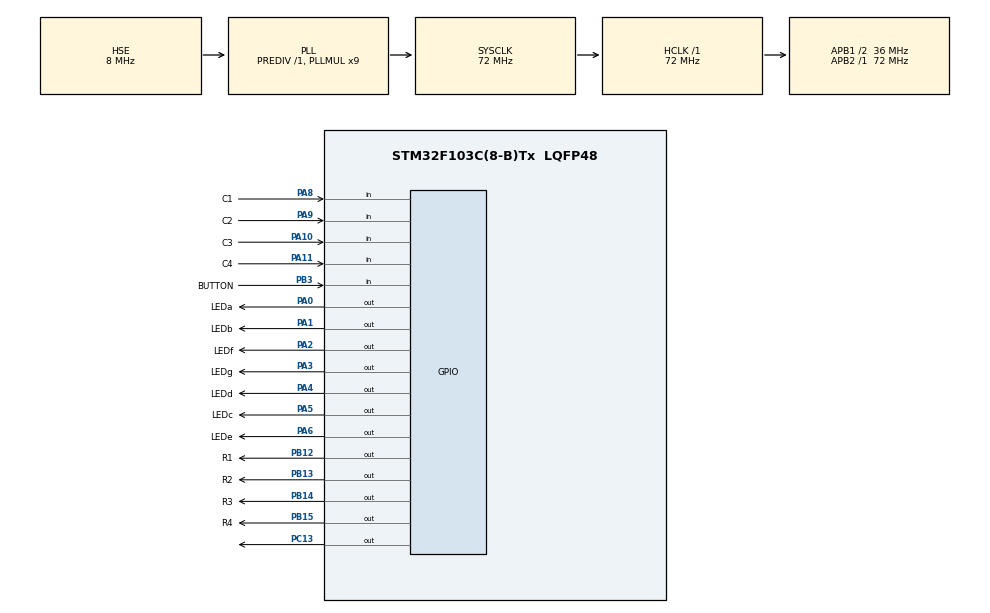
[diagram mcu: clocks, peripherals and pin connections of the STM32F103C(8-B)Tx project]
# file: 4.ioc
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Mcu.Family=STM32F1
Mcu.Name=STM32F103C(8-B)Tx
Mcu.Package=LQFP48
NVIC.PriorityGroup=NVIC_PRIORITYGROUP_4
NVIC.TIM2_IRQn=true\:0\:0\:false\:false\:true\:true\:true\:true
PA0-WKUP.GPIO_Label=LEDa
PA0-WKUP.GPIO_PuPd=GPIO_PULLDOWN
PA0-WKUP.GPIO_Speed=GPIO_SPEED_FREQ_HIGH
PA0-WKUP.Signal=GPIO_Output
PA1.GPIO_Label=LEDb
PA1.GPIO_PuPd=GPIO_PULLDOWN
PA1.GPIO_Speed=GPIO_SPEED_FREQ_HIGH
PA1.Signal=GPIO_Output
PA10.GPIO_Label=C3
PA10.GPIO_PuPd=GPIO_PULLUP
PA10.Signal=GPIO_Input
PA11.GPIO_Label=C4
PA11.GPIO_PuPd=GPIO_PULLUP
PA11.Signal=GPIO_Input
PA13.Mode=Serial_Wire
PA13.Signal=SYS_JTMS-SWDIO
PA14.Mode=Serial_Wire
PA14.Signal=SYS_JTCK-SWCLK
PA2.GPIO_Label=LEDf
PA2.GPIO_PuPd=GPIO_PULLDOWN
PA2.GPIO_Speed=GPIO_SPEED_FREQ_HIGH
PA2.Signal=GPIO_Output
PA3.GPIO_Label=LEDg
PA3.GPIO_PuPd=GPIO_PULLUP
PA3.GPIO_Speed=GPIO_SPEED_FREQ_HIGH
PA3.Signal=GPIO_Output
PA4.GPIO_Label=LEDd
PA4.GPIO_PuPd=GPIO_PULLUP
PA4.GPIO_Speed=GPIO_SPEED_FREQ_HIGH
PA4.Signal=GPIO_Output
PA5.GPIO_Label=LEDc
PA5.GPIO_PuPd=GPIO_PULLUP
PA5.GPIO_Speed=GPIO_SPEED_FREQ_HIGH
PA5.Signal=GPIO_Output
PA6.GPIO_Label=LEDe
PA6.GPIO_PuPd=GPIO_PULLUP
PA6.GPIO_Speed=GPIO_SPEED_FREQ_HIGH
PA6.Signal=GPIO_Output
PA8.GPIO_Label=C1
PA8.GPIO_PuPd=GPIO_PULLUP
PA8.Signal=GPIO_Input
PA9.GPIO_Label=C2
PA9.GPIO_PuPd=GPIO_PULLUP
PA9.Signal=GPIO_Input
PB12.GPIO_Label=R1
PB12.PinState=GPIO_PIN_RESET
PB12.Signal=GPIO_Output
PB13.GPIO_Label=R2
PB13.PinState=GPIO_PIN_RESET
PB13.Signal=GPIO_Output
PB14.GPIO_Label=R3
PB14.PinState=GPIO_PIN_RESET
PB14.Signal=GPIO_Output
PB15.GPIO_Label=R4
PB15.PinState=GPIO_PIN_RESET
PB15.Signal=GPIO_Output
PB3.GPIO_Label=BUTTON
PB3.GPIO_PuPd=GPIO_PULLUP
PB3.Signal=GPIO_Input
PC13-TAMPER-RTC.GPIO_PuPd=GPIO_NOPULL
PC13-TAMPER-RTC.GPIO_Speed=GPIO_SPEED_FREQ_HIGH
PC13-TAMPER-RTC.PinState=GPIO_PIN_SET
PC13-TAMPER-RTC.Signal=GPIO_Output
PD0-OSC_IN.Mode=HSE-External-Oscillator
PD0-OSC_IN.Signal=RCC_OSC_IN
PD1-OSC_OUT.Mode=HSE-External-Oscillator
PD1-OSC_OUT.Signal=RCC_OSC_OUT
ProjectManager.HeapSize=0x200
ProjectManager.StackSize=0x400
ProjectManager.TargetToolchain=Makefile
RCC.AHBFreq_Value=72000000
RCC.APB1CLKDivider=RCC_HCLK_DIV2
RCC.APB1Freq_Value=36000000
RCC.APB1TimFreq_Value=72000000
RCC.APB2Freq_Value=72000000
RCC.APB2TimFreq_Value=72000000
RCC.HCLKFreq_Value=72000000
RCC.PLLMUL=RCC_PLL_MUL9
RCC.PLLSourceVirtual=RCC_PLLSOURCE_HSE
RCC.SYSCLKFreq_VALUE=72000000
RCC.SYSCLKSource=RCC_SYSCLKSOURCE_PLLCLK
RCC.USBFreq_Value=72000000
TIM2.Period=999
TIM2.Prescaler=7199
VP_TIM2_VS_ClockSourceINT.Mode=Internal
board=custom

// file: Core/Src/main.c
/* USER CODE BEGIN Header */
/**
  ******************************************************************************
  * @file           : main.c
  * @brief          : Main program body
  ******************************************************************************
  * @attention
  *
  * Copyright (c) 2024 STMicroelectronics.
  * All rights reserved.
  *
  * This software is licensed under terms that can be found in the LICENSE file
  * in the root directory of this software component.
  * If no LICENSE file comes with this software, it is provided AS-IS.
  *
  ******************************************************************************
  */
/* USER CODE END Header */
#include "main.h"

TIM_HandleTypeDef htim2;

/* USER CODE BEGIN PV */
//!
volatile uint8_t key = 0;
/* USER CODE END PV */

void SystemClock_Config(void);
static void MX_GPIO_Init(void);
static void MX_TIM2_Init(void);
/* USER CODE BEGIN PFP */
//!
void keyPadTick(void);
/* USER CODE END PFP */

int main(void)
{

  /* MCU Configuration--------------------------------------------------------*/

  /* Reset of all peripherals, Initializes the Flash interface and the Systick. */
  HAL_Init();

  /* Configure the system clock */
  SystemClock_Config();

  /* Initialize all configured peripherals */
  MX_GPIO_Init();
  MX_TIM2_Init();
  /* USER CODE BEGIN 2 */
  //!
  // HAL_TIM_Base_Start_IT(&htim2);
  /* USER CODE END 2 */

  /* Infinite loop */
  while (1)
  {

    /* USER CODE BEGIN 3 */
    HAL_GPIO_TogglePin(GPIOC, GPIO_PIN_13);
    HAL_Delay(500);
  }
  /* USER CODE END 3 */
}

void SystemClock_Config(void)
{
  RCC_OscInitTypeDef RCC_OscInitStruct = {0};
  RCC_ClkInitTypeDef RCC_ClkInitStruct = {0};

  /** Initializes the RCC Oscillators according to the specified parameters
  * in the RCC_OscInitTypeDef structure.
  */
  RCC_OscInitStruct.OscillatorType = RCC_OSCILLATORTYPE_HSE;
  RCC_OscInitStruct.HSEState = RCC_HSE_ON;
  RCC_OscInitStruct.HSEPredivValue = RCC_HSE_PREDIV_DIV1;
  RCC_OscInitStruct.HSIState = RCC_HSI_ON;
  RCC_OscInitStruct.PLL.PLLState = RCC_PLL_ON;
  RCC_OscInitStruct.PLL.PLLSource = RCC_PLLSOURCE_HSE;
  RCC_OscInitStruct.PLL.PLLMUL = RCC_PLL_MUL9;
  if (HAL_RCC_OscConfig(&RCC_OscInitStruct) != HAL_OK)
  {
    Error_Handler();
  }

  /** Initializes the CPU, AHB and APB buses clocks
  */
  RCC_ClkInitStruct.ClockType = RCC_CLOCKTYPE_HCLK|RCC_CLOCKTYPE_SYSCLK
                              |RCC_CLOCKTYPE_PCLK1|RCC_CLOCKTYPE_PCLK2;
  RCC_ClkInitStruct.SYSCLKSource = RCC_SYSCLKSOURCE_PLLCLK;
  RCC_ClkInitStruct.AHBCLKDivider = RCC_SYSCLK_DIV1;
  RCC_ClkInitStruct.APB1CLKDivider = RCC_HCLK_DIV2;
  RCC_ClkInitStruct.APB2CLKDivider = RCC_HCLK_DIV1;

  if (HAL_RCC_ClockConfig(&RCC_ClkInitStruct, FLASH_LATENCY_2) != HAL_OK)
  {
    Error_Handler();
  }
}

static void MX_TIM2_Init(void)
{

  TIM_ClockConfigTypeDef sClockSourceConfig = {0};
  TIM_MasterConfigTypeDef sMasterConfig = {0};

  htim2.Instance = TIM2;
  htim2.Init.Prescaler = 7199;
  htim2.Init.CounterMode = TIM_COUNTERMODE_UP;
  htim2.Init.Period = 999;
  htim2.Init.ClockDivision = TIM_CLOCKDIVISION_DIV1;
  htim2.Init.AutoReloadPreload = TIM_AUTORELOAD_PRELOAD_DISABLE;
  if (HAL_TIM_Base_Init(&htim2) != HAL_OK)
  {
    Error_Handler();
  }
  sClockSourceConfig.ClockSource = TIM_CLOCKSOURCE_INTERNAL;
  if (HAL_TIM_ConfigClockSource(&htim2, &sClockSourceConfig) != HAL_OK)
  {
    Error_Handler();
  }
  sMasterConfig.MasterOutputTrigger = TIM_TRGO_RESET;
  sMasterConfig.MasterSlaveMode = TIM_MASTERSLAVEMODE_DISABLE;
  if (HAL_TIMEx_MasterConfigSynchronization(&htim2, &sMasterConfig) != HAL_OK)
  {
    Error_Handler();
  }

}

static void MX_GPIO_Init(void)
{
  GPIO_InitTypeDef GPIO_InitStruct = {0};

  /* GPIO Ports Clock Enable */
  __HAL_RCC_GPIOC_CLK_ENABLE();
  __HAL_RCC_GPIOD_CLK_ENABLE();
  __HAL_RCC_GPIOA_CLK_ENABLE();
  __HAL_RCC_GPIOB_CLK_ENABLE();

  /*Configure GPIO pin Output Level */
  HAL_GPIO_WritePin(GPIOC, GPIO_PIN_13, GPIO_PIN_SET);

  /*Configure GPIO pin Output Level */
  HAL_GPIO_WritePin(GPIOA, LEDa_Pin|LEDb_Pin|LEDf_Pin|LEDg_Pin
                          |LEDd_Pin|LEDc_Pin|LEDe_Pin, GPIO_PIN_RESET);

  /*Configure GPIO pin Output Level */
  HAL_GPIO_WritePin(GPIOB, R1_Pin|R2_Pin|R3_Pin|R4_Pin, GPIO_PIN_RESET);

  /*Configure GPIO pin : PC13 */
  GPIO_InitStruct.Pin = GPIO_PIN_13;
  GPIO_InitStruct.Mode = GPIO_MODE_OUTPUT_PP;
  GPIO_InitStruct.Pull = GPIO_NOPULL;
  GPIO_InitStruct.Speed = GPIO_SPEED_FREQ_HIGH;
  HAL_GPIO_Init(GPIOC, &GPIO_InitStruct);

  /*Configure GPIO pins : LEDa_Pin LEDb_Pin LEDf_Pin */
  GPIO_InitStruct.Pin = LEDa_Pin|LEDb_Pin|LEDf_Pin;
  GPIO_InitStruct.Mode = GPIO_MODE_OUTPUT_PP;
  GPIO_InitStruct.Pull = GPIO_PULLDOWN;
  GPIO_InitStruct.Speed = GPIO_SPEED_FREQ_HIGH;
  HAL_GPIO_Init(GPIOA, &GPIO_InitStruct);

  /*Configure GPIO pins : LEDg_Pin LEDd_Pin LEDc_Pin LEDe_Pin */
  GPIO_InitStruct.Pin = LEDg_Pin|LEDd_Pin|LEDc_Pin|LEDe_Pin;
  GPIO_InitStruct.Mode = GPIO_MODE_OUTPUT_PP;
  GPIO_InitStruct.Pull = GPIO_PULLUP;
  GPIO_InitStruct.Speed = GPIO_SPEED_FREQ_HIGH;
  HAL_GPIO_Init(GPIOA, &GPIO_InitStruct);

  /*Configure GPIO pins : R1_Pin R2_Pin R3_Pin R4_Pin */
  GPIO_InitStruct.Pin = R1_Pin|R2_Pin|R3_Pin|R4_Pin;
  GPIO_InitStruct.Mode = GPIO_MODE_OUTPUT_PP;
  GPIO_InitStruct.Pull = GPIO_NOPULL;
  GPIO_InitStruct.Speed = GPIO_SPEED_FREQ_LOW;
  HAL_GPIO_Init(GPIOB, &GPIO_InitStruct);

  /*Configure GPIO pins : C1_Pin C2_Pin C3_Pin C4_Pin */
  GPIO_InitStruct.Pin = C1_Pin|C2_Pin|C3_Pin|C4_Pin;
  GPIO_InitStruct.Mode = GPIO_MODE_INPUT;
  GPIO_InitStruct.Pull = GPIO_PULLUP;
  HAL_GPIO_Init(GPIOA, &GPIO_InitStruct);

  /*Configure GPIO pin : BUTTON_Pin */
  GPIO_InitStruct.Pin = BUTTON_Pin;
  GPIO_InitStruct.Mode = GPIO_MODE_INPUT;
  GPIO_InitStruct.Pull = GPIO_PULLUP;
  HAL_GPIO_Init(BUTTON_GPIO_Port, &GPIO_InitStruct);

}

/* USER CODE BEGIN 4 */
//!

/*
підключити до мікроконтролера кнопку. Написати програму, в якій після натискання
на клавіатурі на кнопку "А" на семисегментний індикатор починає кожні 100 мc
виводитись випадкове число в діапазоні від 0 до 9. У разі короткого натискання
на підключену додаткову кнопку генерація чисел припиняється, за користувацький
світлодіод має блимнути стільки разів, скільки показано на індикаторі. Натискання
кнопки "В" на клавіатурі має запускати блимання світлодіода повторно. Довге натискання
на підключену додаткову кнопку має запускати генерацію заново.
*/
void keyPadTick(void){
  // key = read_keypad();
  // HAL_GPIO_WritePin(GPIOC, GPIO_PIN_13 ,
  //   ((key!=0)?GPIO_PIN_SET:GPIO_PIN_RESET)
  // );
  // HAL_GPIO_WritePin(GPIOC, GPIO_PIN_13,
  //   (0)?GPIO_PIN_SET:GPIO_PIN_RESET
  // );
  // displayChar(key);
}
/* USER CODE END 4 */

void Error_Handler(void)
{
  __disable_irq();
  while (1)
  {
  }
}
